# ESP32-S31 register map
Vendor: ESPRESSIF SYSTEMS (SHANGHAI) CO., LTD.; Series: ESP32 S-Series; File version: 1
CPU: RV32IMAFC r0p0, little endian, no MPU, FPU, 0 interrupt priority bits
Address unit: 32 bits
Registers are 32-bit, read-write, reset 0x0 unless marked. A register's access mark holds for its fields unless they carry their own. Offsets are from the block's base; [hi:lo] are bit positions; {n}, {i} and the like mark numbered series; 'fields as' and 'values as' point back to an identical list.

## HP_SYS_CLKRST — HP_SYS_CLKRST Peripheral
Base 0x20587000
0x00 SOC_CLK_SEL — need_des
  [1:0] REG_SOC_CLK_SEL — Configures to select the clock source of HP_ROOT_CLK.\\ 0 (default): XTAL_CLK\\ 1: PLL_F300M_CLK\\ 2: RC_FAST_CLK\\
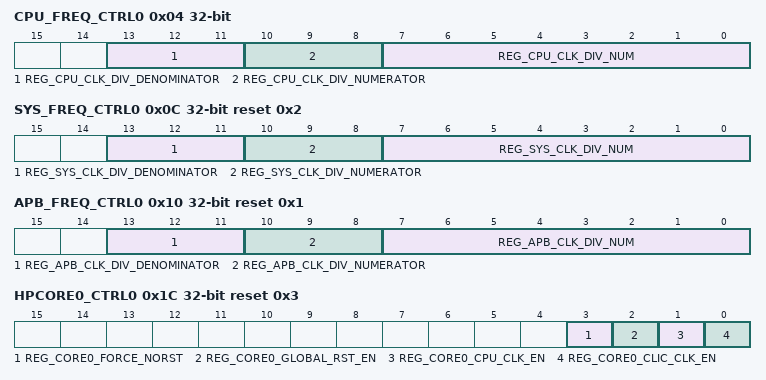
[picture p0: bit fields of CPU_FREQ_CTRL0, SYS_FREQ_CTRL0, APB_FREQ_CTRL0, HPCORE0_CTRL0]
0x04 CPU_FREQ_CTRL0 — need_des
  [13:11] REG_CPU_CLK_DIV_DENOMINATOR — need_des
  [10:8] REG_CPU_CLK_DIV_NUMERATOR — need_des
  [7:0] REG_CPU_CLK_DIV_NUM — need_des
0x08 MEM_FREQ_CTRL0 reset 0x1 — need_des
  [0] REG_MEM_CLK_DIV_NUM
0x0C SYS_FREQ_CTRL0 reset 0x2 — need_des
  [13:11] REG_SYS_CLK_DIV_DENOMINATOR — need_des
  [10:8] REG_SYS_CLK_DIV_NUMERATOR — need_des
  [7:0] REG_SYS_CLK_DIV_NUM — need_des
0x10 APB_FREQ_CTRL0 reset 0x1 — need_des
  [13:11] REG_APB_CLK_DIV_DENOMINATOR — need_des
  [10:8] REG_APB_CLK_DIV_NUMERATOR — need_des
  [7:0] REG_APB_CLK_DIV_NUM — need_des
0x14 ROOT_CLK_CTRL0 — need_des
  [0] REG_SOC_CLK_UPDATE
0x18 CPU_WFI_DELAY_CTRL0 — need_des
  [3:0] REG_CPUICM_DELAY_NUM
0x1C HPCORE0_CTRL0 reset 0x3 — need_des
  [3] REG_CORE0_FORCE_NORST — need_des
  [2] REG_CORE0_GLOBAL_RST_EN — need_des
  [1] REG_CORE0_CPU_CLK_EN — need_des
  [0] REG_CORE0_CLIC_CLK_EN — need_des
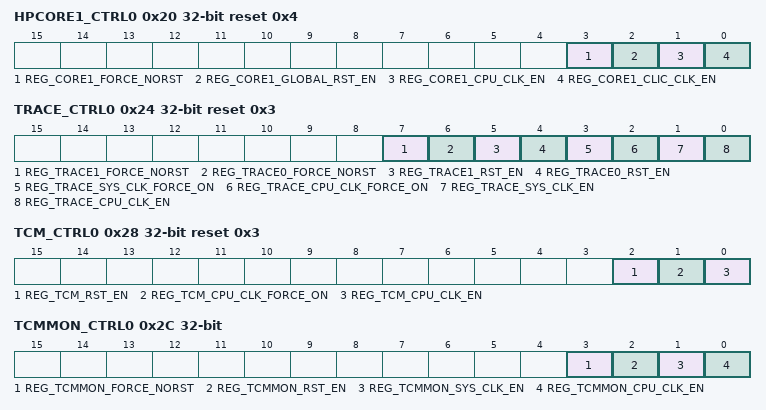
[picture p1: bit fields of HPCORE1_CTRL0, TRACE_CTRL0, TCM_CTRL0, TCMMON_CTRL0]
0x20 HPCORE1_CTRL0 reset 0x4 — need_des
  [3] REG_CORE1_FORCE_NORST — need_des
  [2] REG_CORE1_GLOBAL_RST_EN — need_des
  [1] REG_CORE1_CPU_CLK_EN — need_des
  [0] REG_CORE1_CLIC_CLK_EN — need_des
0x24 TRACE_CTRL0 reset 0x3 — need_des
  [7] REG_TRACE1_FORCE_NORST — need_des
  [6] REG_TRACE0_FORCE_NORST — need_des
  [5] REG_TRACE1_RST_EN — need_des
  [4] REG_TRACE0_RST_EN — need_des
  [3] REG_TRACE_SYS_CLK_FORCE_ON — need_des
  [2] REG_TRACE_CPU_CLK_FORCE_ON — need_des
  [1] REG_TRACE_SYS_CLK_EN — need_des
  [0] REG_TRACE_CPU_CLK_EN — need_des
0x28 TCM_CTRL0 reset 0x3 — need_des
  [2] REG_TCM_RST_EN — need_des
  [1] REG_TCM_CPU_CLK_FORCE_ON — need_des
  [0] REG_TCM_CPU_CLK_EN — need_des
0x2C TCMMON_CTRL0 — need_des
  [3] REG_TCMMON_FORCE_NORST — need_des
  [2] REG_TCMMON_RST_EN — need_des
  [1] REG_TCMMON_SYS_CLK_EN — need_des
  [0] REG_TCMMON_CPU_CLK_EN — need_des
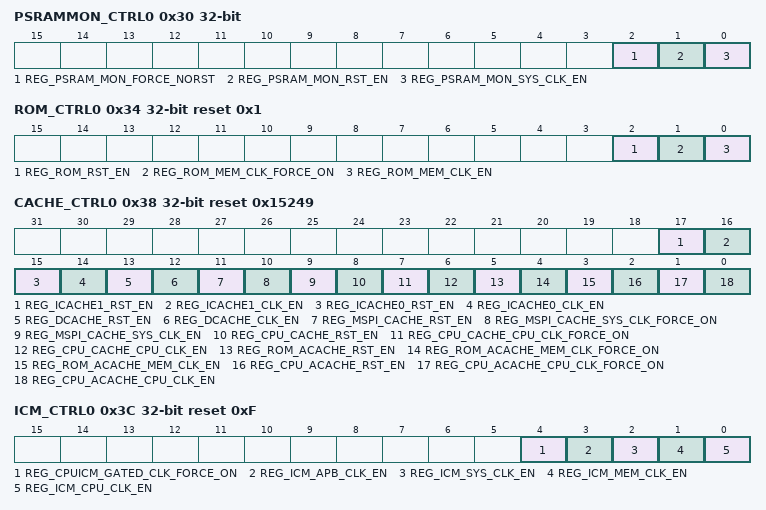
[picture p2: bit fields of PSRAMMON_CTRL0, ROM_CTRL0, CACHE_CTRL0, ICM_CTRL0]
0x30 PSRAMMON_CTRL0 — need_des
  [2] REG_PSRAM_MON_FORCE_NORST — need_des
  [1] REG_PSRAM_MON_RST_EN — need_des
  [0] REG_PSRAM_MON_SYS_CLK_EN — need_des
0x34 ROM_CTRL0 reset 0x1 — need_des
  [2] REG_ROM_RST_EN — need_des
  [1] REG_ROM_MEM_CLK_FORCE_ON — need_des
  [0] REG_ROM_MEM_CLK_EN — need_des
0x38 CACHE_CTRL0 reset 0x15249 — need_des
  [17] REG_ICACHE1_RST_EN — need_des
  [16] REG_ICACHE1_CLK_EN — need_des
  [15] REG_ICACHE0_RST_EN — need_des
  [14] REG_ICACHE0_CLK_EN — need_des
  [13] REG_DCACHE_RST_EN — need_des
  [12] REG_DCACHE_CLK_EN — need_des
  [11] REG_MSPI_CACHE_RST_EN — need_des
  [10] REG_MSPI_CACHE_SYS_CLK_FORCE_ON — need_des
  [9] REG_MSPI_CACHE_SYS_CLK_EN — need_des
  [8] REG_CPU_CACHE_RST_EN — need_des
  [7] REG_CPU_CACHE_CPU_CLK_FORCE_ON — need_des
  [6] REG_CPU_CACHE_CPU_CLK_EN — need_des
  [5] REG_ROM_ACACHE_RST_EN — need_des
  [4] REG_ROM_ACACHE_MEM_CLK_FORCE_ON — need_des
  [3] REG_ROM_ACACHE_MEM_CLK_EN — need_des
  [2] REG_CPU_ACACHE_RST_EN — need_des
  [1] REG_CPU_ACACHE_CPU_CLK_FORCE_ON — need_des
  [0] REG_CPU_ACACHE_CPU_CLK_EN — need_des
0x3C ICM_CTRL0 reset 0xF — need_des
  [4] REG_CPUICM_GATED_CLK_FORCE_ON — need_des
  [3] REG_ICM_APB_CLK_EN — need_des
  [2] REG_ICM_SYS_CLK_EN — need_des
  [1] REG_ICM_MEM_CLK_EN — need_des
  [0] REG_ICM_CPU_CLK_EN — need_des
0x40 MODEM_CTRL0 reset 0x1 — need_des
  [0] REG_MODEM_CLK_EN
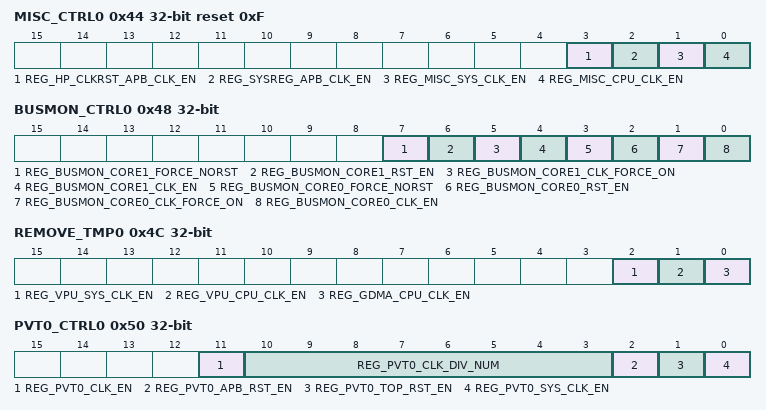
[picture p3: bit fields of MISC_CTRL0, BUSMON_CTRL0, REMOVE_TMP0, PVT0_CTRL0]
0x44 MISC_CTRL0 reset 0xF — need_des
  [3] REG_HP_CLKRST_APB_CLK_EN — need_des
  [2] REG_SYSREG_APB_CLK_EN — need_des
  [1] REG_MISC_SYS_CLK_EN — need_des
  [0] REG_MISC_CPU_CLK_EN — need_des
0x48 BUSMON_CTRL0 — need_des
  [7] REG_BUSMON_CORE1_FORCE_NORST — need_des
  [6] REG_BUSMON_CORE1_RST_EN — need_des
  [5] REG_BUSMON_CORE1_CLK_FORCE_ON — need_des
  [4] REG_BUSMON_CORE1_CLK_EN — need_des
  [3] REG_BUSMON_CORE0_FORCE_NORST — need_des
  [2] REG_BUSMON_CORE0_RST_EN — need_des
  [1] REG_BUSMON_CORE0_CLK_FORCE_ON — need_des
  [0] REG_BUSMON_CORE0_CLK_EN — need_des
0x4C REMOVE_TMP0 — need_des
  [2] REG_VPU_SYS_CLK_EN — need_des
  [1] REG_VPU_CPU_CLK_EN — need_des
  [0] REG_GDMA_CPU_CLK_EN — need_des
0x50 PVT0_CTRL0 — need_des
  [11] REG_PVT0_CLK_EN — need_des
  [10:3] REG_PVT0_CLK_DIV_NUM — need_des
  [2] REG_PVT0_APB_RST_EN — need_des
  [1] REG_PVT0_TOP_RST_EN — need_des
  [0] REG_PVT0_SYS_CLK_EN — need_des
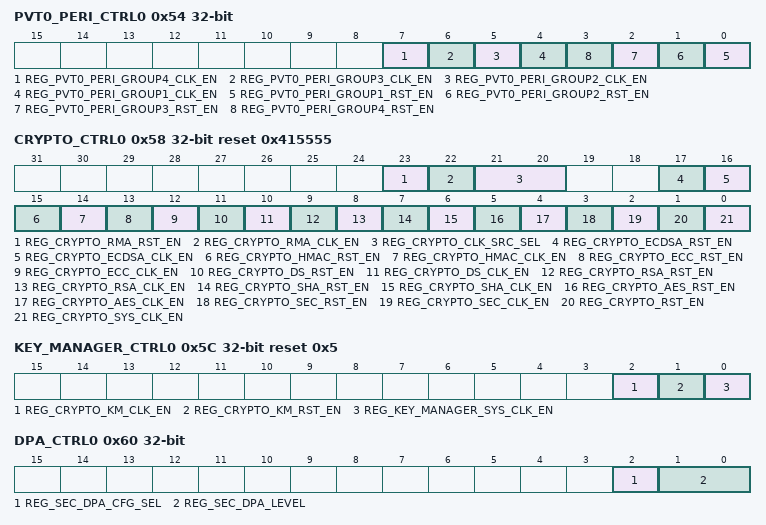
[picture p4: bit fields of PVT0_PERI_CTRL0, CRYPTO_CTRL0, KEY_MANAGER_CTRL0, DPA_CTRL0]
0x54 PVT0_PERI_CTRL0 — need_des
  [7] REG_PVT0_PERI_GROUP4_CLK_EN — modem power domian pvt clk en
  [6] REG_PVT0_PERI_GROUP3_CLK_EN — modem power domian pvt clk en
  [5] REG_PVT0_PERI_GROUP2_CLK_EN — TOP power domian pvt clk en
  [4] REG_PVT0_PERI_GROUP1_CLK_EN — TOP power domian pvt clk en
  [n-1] REG_PVT0_PERI_GROUP{n}_RST_EN (n=1..4) — need_des
0x58 CRYPTO_CTRL0 reset 0x415555 — need_des
  [23] REG_CRYPTO_RMA_RST_EN — need_des
  [22] REG_CRYPTO_RMA_CLK_EN — need_des
  [21:20] REG_CRYPTO_CLK_SRC_SEL — need_des
  [17] REG_CRYPTO_ECDSA_RST_EN — need_des
  [16] REG_CRYPTO_ECDSA_CLK_EN — need_des
  [15] REG_CRYPTO_HMAC_RST_EN — need_des
  [14] REG_CRYPTO_HMAC_CLK_EN — need_des
  [13] REG_CRYPTO_ECC_RST_EN — need_des
  [12] REG_CRYPTO_ECC_CLK_EN — need_des
  [11] REG_CRYPTO_DS_RST_EN — need_des
  [10] REG_CRYPTO_DS_CLK_EN — need_des
  [9] REG_CRYPTO_RSA_RST_EN — need_des
  [8] REG_CRYPTO_RSA_CLK_EN — need_des
  [7] REG_CRYPTO_SHA_RST_EN — need_des
  [6] REG_CRYPTO_SHA_CLK_EN — need_des
  [5] REG_CRYPTO_AES_RST_EN — need_des
  [4] REG_CRYPTO_AES_CLK_EN — need_des
  [3] REG_CRYPTO_SEC_RST_EN — need_des
  [2] REG_CRYPTO_SEC_CLK_EN — need_des
  [1] REG_CRYPTO_RST_EN — need_des
  [0] REG_CRYPTO_SYS_CLK_EN — need_des
0x5C KEY_MANAGER_CTRL0 reset 0x5 — need_des
  [2] REG_CRYPTO_KM_CLK_EN — need_des
  [1] REG_CRYPTO_KM_RST_EN — need_des
  [0] REG_KEY_MANAGER_SYS_CLK_EN — need_des
0x60 DPA_CTRL0 — need_des
  [2] REG_SEC_DPA_CFG_SEL — need_des
  [1:0] REG_SEC_DPA_LEVEL — need_des
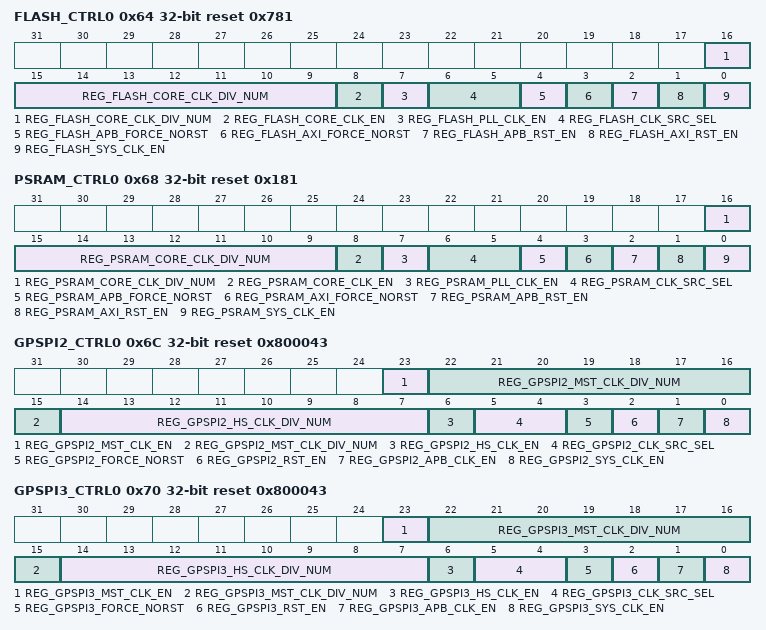
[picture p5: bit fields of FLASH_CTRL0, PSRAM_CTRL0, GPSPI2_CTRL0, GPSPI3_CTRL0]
0x64 FLASH_CTRL0 reset 0x781 — need_des
  [16:9] REG_FLASH_CORE_CLK_DIV_NUM — need_des
  [8] REG_FLASH_CORE_CLK_EN — need_des
  [7] REG_FLASH_PLL_CLK_EN — need_des
  [6:5] REG_FLASH_CLK_SRC_SEL — need_des
  [4] REG_FLASH_APB_FORCE_NORST — need_des
  [3] REG_FLASH_AXI_FORCE_NORST — need_des
  [2] REG_FLASH_APB_RST_EN — need_des
  [1] REG_FLASH_AXI_RST_EN — need_des
  [0] REG_FLASH_SYS_CLK_EN — need_des
0x68 PSRAM_CTRL0 reset 0x181 — need_des
  [16:9] REG_PSRAM_CORE_CLK_DIV_NUM — need_des
  [8] REG_PSRAM_CORE_CLK_EN — need_des
  [7] REG_PSRAM_PLL_CLK_EN — need_des
  [6:5] REG_PSRAM_CLK_SRC_SEL — need_des
  [4] REG_PSRAM_APB_FORCE_NORST — need_des
  [3] REG_PSRAM_AXI_FORCE_NORST — need_des
  [2] REG_PSRAM_APB_RST_EN — need_des
  [1] REG_PSRAM_AXI_RST_EN — need_des
  [0] REG_PSRAM_SYS_CLK_EN — need_des
0x6C GPSPI2_CTRL0 reset 0x800043 — need_des
  [23] REG_GPSPI2_MST_CLK_EN — need_des
  [22:15] REG_GPSPI2_MST_CLK_DIV_NUM — need_des
  [14:7] REG_GPSPI2_HS_CLK_DIV_NUM — need_des
  [6] REG_GPSPI2_HS_CLK_EN — need_des
  [5:4] REG_GPSPI2_CLK_SRC_SEL — need_des
  [3] REG_GPSPI2_FORCE_NORST — need_des
  [2] REG_GPSPI2_RST_EN — need_des
  [1] REG_GPSPI2_APB_CLK_EN — need_des
  [0] REG_GPSPI2_SYS_CLK_EN — need_des
0x70 GPSPI3_CTRL0 reset 0x800043 — need_des
  [23] REG_GPSPI3_MST_CLK_EN — need_des
  [22:15] REG_GPSPI3_MST_CLK_DIV_NUM — need_des
  [14:7] REG_GPSPI3_HS_CLK_DIV_NUM — need_des
  [6] REG_GPSPI3_HS_CLK_EN — need_des
  [5:4] REG_GPSPI3_CLK_SRC_SEL — need_des
  [3] REG_GPSPI3_FORCE_NORST — need_des
  [2] REG_GPSPI3_RST_EN — need_des
  [1] REG_GPSPI3_APB_CLK_EN — need_des
  [0] REG_GPSPI3_SYS_CLK_EN — need_des
0x74 GDMA_CTRL0 — need_des
  [0] REG_GDMA_SYS_CLK_EN
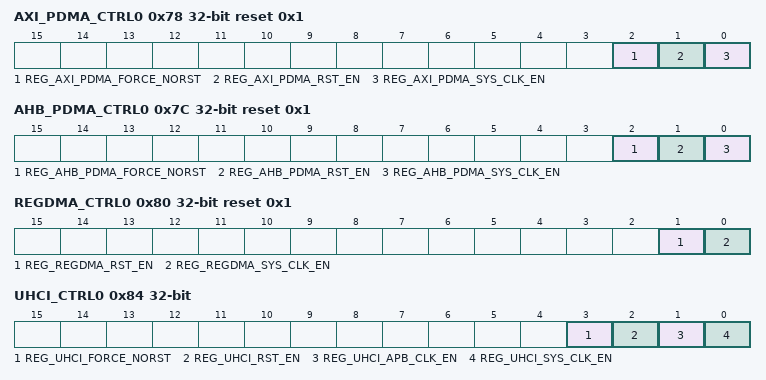
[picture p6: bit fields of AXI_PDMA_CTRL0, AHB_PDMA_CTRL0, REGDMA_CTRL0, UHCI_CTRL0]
0x78 AXI_PDMA_CTRL0 reset 0x1 — need_des
  [2] REG_AXI_PDMA_FORCE_NORST — need_des
  [1] REG_AXI_PDMA_RST_EN — need_des
  [0] REG_AXI_PDMA_SYS_CLK_EN — need_des
0x7C AHB_PDMA_CTRL0 reset 0x1 — need_des
  [2] REG_AHB_PDMA_FORCE_NORST — need_des
  [1] REG_AHB_PDMA_RST_EN — need_des
  [0] REG_AHB_PDMA_SYS_CLK_EN — need_des
0x80 REGDMA_CTRL0 reset 0x1 — need_des
  [1] REG_REGDMA_RST_EN — need_des
  [0] REG_REGDMA_SYS_CLK_EN — need_des
0x84 UHCI_CTRL0 — need_des
  [3] REG_UHCI_FORCE_NORST — need_des
  [2] REG_UHCI_RST_EN — need_des
  [1] REG_UHCI_APB_CLK_EN — need_des
  [0] REG_UHCI_SYS_CLK_EN — need_des
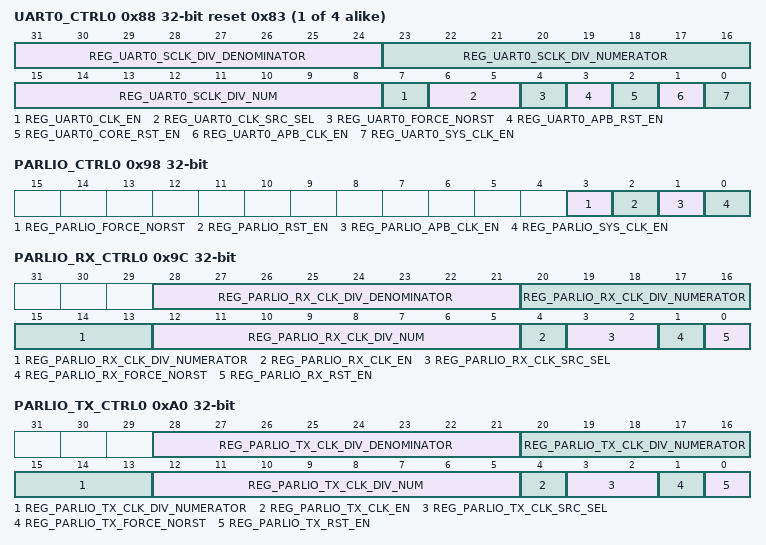
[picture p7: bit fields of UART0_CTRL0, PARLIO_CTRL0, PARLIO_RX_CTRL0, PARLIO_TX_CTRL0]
{0x88+4i} UART{i}_CTRL0 reset 0x83 (i=0..3) — need_des
  [31:24] REG_UART{i}_SCLK_DIV_DENOMINATOR — need_des
  [23:16] REG_UART{i}_SCLK_DIV_NUMERATOR — need_des
  [15:8] REG_UART{i}_SCLK_DIV_NUM — need_des
  [7] REG_UART{i}_CLK_EN — need_des
  [6:5] REG_UART{i}_CLK_SRC_SEL — need_des
  [4] REG_UART{i}_FORCE_NORST — need_des
  [3] REG_UART{i}_APB_RST_EN — need_des
  [2] REG_UART{i}_CORE_RST_EN — need_des
  [1] REG_UART{i}_APB_CLK_EN — need_des
  [0] REG_UART{i}_SYS_CLK_EN — need_des
0x98 PARLIO_CTRL0 — need_des
  [3] REG_PARLIO_FORCE_NORST — need_des
  [2] REG_PARLIO_RST_EN — need_des
  [1] REG_PARLIO_APB_CLK_EN — need_des
  [0] REG_PARLIO_SYS_CLK_EN — need_des
0x9C PARLIO_RX_CTRL0 — need_des
  [28:21] REG_PARLIO_RX_CLK_DIV_DENOMINATOR — need_des
  [20:13] REG_PARLIO_RX_CLK_DIV_NUMERATOR — need_des
  [12:5] REG_PARLIO_RX_CLK_DIV_NUM — need_des
  [4] REG_PARLIO_RX_CLK_EN — need_des
  [3:2] REG_PARLIO_RX_CLK_SRC_SEL — need_des
  [1] REG_PARLIO_RX_FORCE_NORST — need_des
  [0] REG_PARLIO_RX_RST_EN — need_des
0xA0 PARLIO_TX_CTRL0 — need_des
  [28:21] REG_PARLIO_TX_CLK_DIV_DENOMINATOR — need_des
  [20:13] REG_PARLIO_TX_CLK_DIV_NUMERATOR — need_des
  [12:5] REG_PARLIO_TX_CLK_DIV_NUM — need_des
  [4] REG_PARLIO_TX_CLK_EN — need_des
  [3:2] REG_PARLIO_TX_CLK_SRC_SEL — need_des
  [1] REG_PARLIO_TX_FORCE_NORST — need_des
  [0] REG_PARLIO_TX_RST_EN — need_des
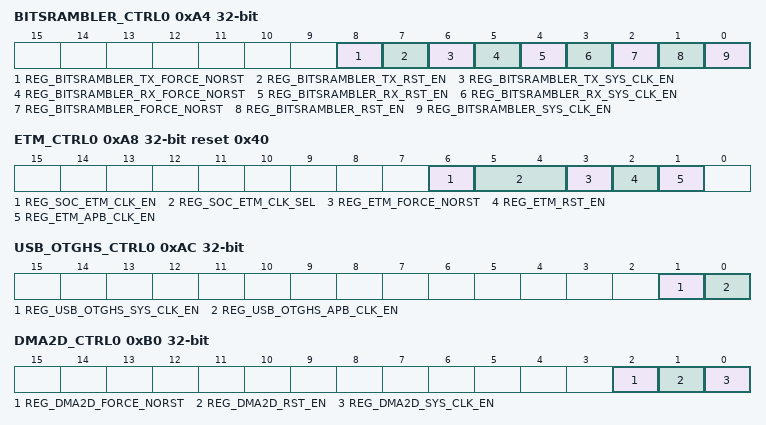
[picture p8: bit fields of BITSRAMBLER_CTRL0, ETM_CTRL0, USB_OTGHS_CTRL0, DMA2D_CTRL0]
0xA4 BITSRAMBLER_CTRL0 — need_des
  [8] REG_BITSRAMBLER_TX_FORCE_NORST — need_des
  [7] REG_BITSRAMBLER_TX_RST_EN — need_des
  [6] REG_BITSRAMBLER_TX_SYS_CLK_EN — need_des
  [5] REG_BITSRAMBLER_RX_FORCE_NORST — need_des
  [4] REG_BITSRAMBLER_RX_RST_EN — need_des
  [3] REG_BITSRAMBLER_RX_SYS_CLK_EN — need_des
  [2] REG_BITSRAMBLER_FORCE_NORST — need_des
  [1] REG_BITSRAMBLER_RST_EN — need_des
  [0] REG_BITSRAMBLER_SYS_CLK_EN — need_des
0xA8 ETM_CTRL0 reset 0x40 — need_des
  [6] REG_SOC_ETM_CLK_EN — need_des
  [5:4] REG_SOC_ETM_CLK_SEL — need_des
  [3] REG_ETM_FORCE_NORST — need_des
  [2] REG_ETM_RST_EN — need_des
  [1] REG_ETM_APB_CLK_EN — need_des
0xAC USB_OTGHS_CTRL0 — need_des
  [1] REG_USB_OTGHS_SYS_CLK_EN — need_des
  [0] REG_USB_OTGHS_APB_CLK_EN — need_des
0xB0 DMA2D_CTRL0 — need_des
  [2] REG_DMA2D_FORCE_NORST — need_des
  [1] REG_DMA2D_RST_EN — need_des
  [0] REG_DMA2D_SYS_CLK_EN — need_des
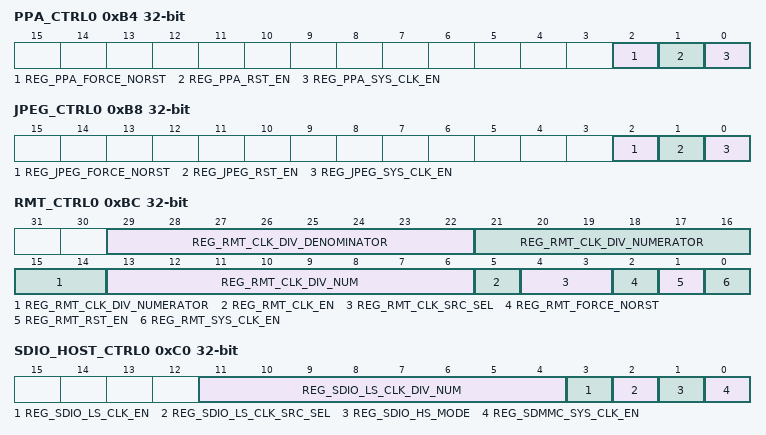
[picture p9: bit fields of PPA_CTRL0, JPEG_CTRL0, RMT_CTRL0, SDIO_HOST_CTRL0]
0xB4 PPA_CTRL0 — need_des
  [2] REG_PPA_FORCE_NORST — need_des
  [1] REG_PPA_RST_EN — need_des
  [0] REG_PPA_SYS_CLK_EN — need_des
0xB8 JPEG_CTRL0 — need_des
  [2] REG_JPEG_FORCE_NORST — need_des
  [1] REG_JPEG_RST_EN — need_des
  [0] REG_JPEG_SYS_CLK_EN — need_des
0xBC RMT_CTRL0 — need_des
  [29:22] REG_RMT_CLK_DIV_DENOMINATOR — need_des
  [21:14] REG_RMT_CLK_DIV_NUMERATOR — need_des
  [13:6] REG_RMT_CLK_DIV_NUM — need_des
  [5] REG_RMT_CLK_EN — need_des
  [4:3] REG_RMT_CLK_SRC_SEL — need_des
  [2] REG_RMT_FORCE_NORST — need_des
  [1] REG_RMT_RST_EN — need_des
  [0] REG_RMT_SYS_CLK_EN — need_des
0xC0 SDIO_HOST_CTRL0 — need_des
  [11:4] REG_SDIO_LS_CLK_DIV_NUM — need_des
  [3] REG_SDIO_LS_CLK_EN — need_des
  [2] REG_SDIO_LS_CLK_SRC_SEL — reserved
  [1] REG_SDIO_HS_MODE — reserved
  [0] REG_SDMMC_SYS_CLK_EN — need_des
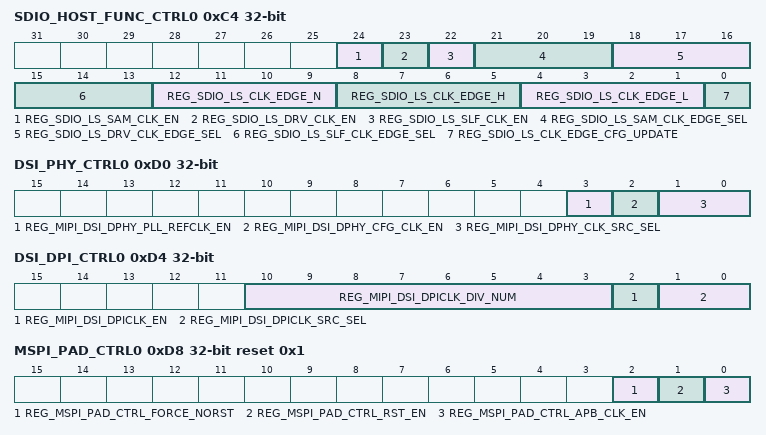
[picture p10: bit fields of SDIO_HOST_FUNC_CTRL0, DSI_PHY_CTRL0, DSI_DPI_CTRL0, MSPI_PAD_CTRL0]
0xC4 SDIO_HOST_FUNC_CTRL0 access per field — need_des
  [24] REG_SDIO_LS_SAM_CLK_EN rw — need_des
  [23] REG_SDIO_LS_DRV_CLK_EN rw — need_des
  [22] REG_SDIO_LS_SLF_CLK_EN rw — need_des
  [21:19] REG_SDIO_LS_SAM_CLK_EDGE_SEL rw — need_des
  [18:16] REG_SDIO_LS_DRV_CLK_EDGE_SEL rw — need_des
  [15:13] REG_SDIO_LS_SLF_CLK_EDGE_SEL rw — need_des
  [12:9] REG_SDIO_LS_CLK_EDGE_N rw — need_des
  [8:5] REG_SDIO_LS_CLK_EDGE_H rw — need_des
  [4:1] REG_SDIO_LS_CLK_EDGE_L rw — need_des
  [0] REG_SDIO_LS_CLK_EDGE_CFG_UPDATE wo — need_des
0xC8 EMAC_CTRL0 — need_des
  [0] REG_EMAC_SYS_CLK_EN
0xCC DSI_CTRL0 — need_des
  [0] REG_DSI_SYS_CLK_EN
0xD0 DSI_PHY_CTRL0 — need_des
  [3] REG_MIPI_DSI_DPHY_PLL_REFCLK_EN — need_des
  [2] REG_MIPI_DSI_DPHY_CFG_CLK_EN — need_des
  [1:0] REG_MIPI_DSI_DPHY_CLK_SRC_SEL — need_des
0xD4 DSI_DPI_CTRL0 — need_des
  [10:3] REG_MIPI_DSI_DPICLK_DIV_NUM — need_des
  [2] REG_MIPI_DSI_DPICLK_EN — need_des
  [1:0] REG_MIPI_DSI_DPICLK_SRC_SEL — need_des
0xD8 MSPI_PAD_CTRL0 reset 0x1 — need_des
  [2] REG_MSPI_PAD_CTRL_FORCE_NORST — need_des
  [1] REG_MSPI_PAD_CTRL_RST_EN — need_des
  [0] REG_MSPI_PAD_CTRL_APB_CLK_EN — need_des
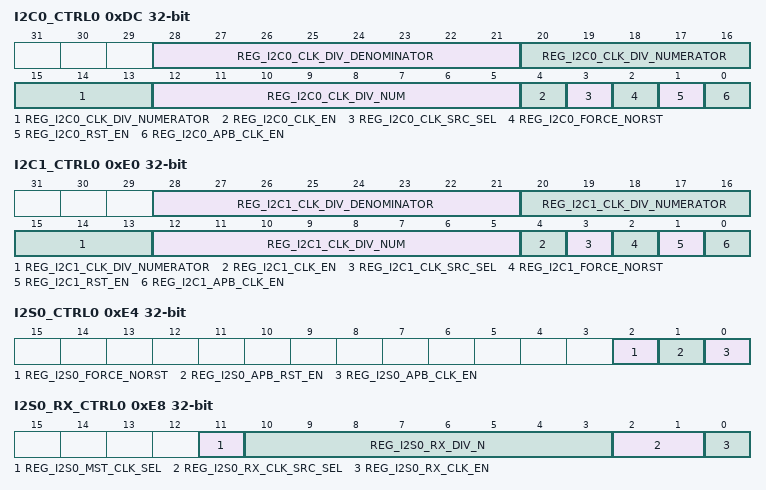
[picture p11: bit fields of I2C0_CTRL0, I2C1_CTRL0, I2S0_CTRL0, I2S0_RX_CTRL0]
0xDC I2C0_CTRL0 — need_des
  [28:21] REG_I2C0_CLK_DIV_DENOMINATOR — need_des
  [20:13] REG_I2C0_CLK_DIV_NUMERATOR — need_des
  [12:5] REG_I2C0_CLK_DIV_NUM — need_des
  [4] REG_I2C0_CLK_EN — need_des
  [3] REG_I2C0_CLK_SRC_SEL — need_des
  [2] REG_I2C0_FORCE_NORST — need_des
  [1] REG_I2C0_RST_EN — need_des
  [0] REG_I2C0_APB_CLK_EN — need_des
0xE0 I2C1_CTRL0 — need_des
  [28:21] REG_I2C1_CLK_DIV_DENOMINATOR — need_des
  [20:13] REG_I2C1_CLK_DIV_NUMERATOR — need_des
  [12:5] REG_I2C1_CLK_DIV_NUM — need_des
  [4] REG_I2C1_CLK_EN — need_des
  [3] REG_I2C1_CLK_SRC_SEL — need_des
  [2] REG_I2C1_FORCE_NORST — need_des
  [1] REG_I2C1_RST_EN — need_des
  [0] REG_I2C1_APB_CLK_EN — need_des
0xE4 I2S0_CTRL0 — need_des
  [2] REG_I2S0_FORCE_NORST — need_des
  [1] REG_I2S0_APB_RST_EN — need_des
  [0] REG_I2S0_APB_CLK_EN — need_des
0xE8 I2S0_RX_CTRL0 — need_des
  [11] REG_I2S0_MST_CLK_SEL — need_des
  [10:3] REG_I2S0_RX_DIV_N — need_des
  [2:1] REG_I2S0_RX_CLK_SRC_SEL — need_des
  [0] REG_I2S0_RX_CLK_EN — need_des
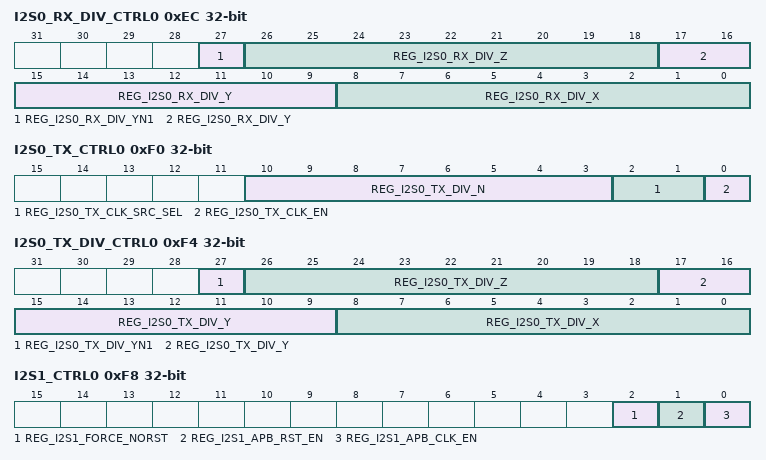
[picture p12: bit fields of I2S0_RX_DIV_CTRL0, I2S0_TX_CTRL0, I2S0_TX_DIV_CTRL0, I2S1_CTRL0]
0xEC I2S0_RX_DIV_CTRL0 — need_des
  [27] REG_I2S0_RX_DIV_YN1 — need_des
  [26:18] REG_I2S0_RX_DIV_Z — need_des
  [17:9] REG_I2S0_RX_DIV_Y — need_des
  [8:0] REG_I2S0_RX_DIV_X — need_des
0xF0 I2S0_TX_CTRL0 — need_des
  [10:3] REG_I2S0_TX_DIV_N — need_des
  [2:1] REG_I2S0_TX_CLK_SRC_SEL — need_des
  [0] REG_I2S0_TX_CLK_EN — need_des
0xF4 I2S0_TX_DIV_CTRL0 — need_des
  [27] REG_I2S0_TX_DIV_YN1 — need_des
  [26:18] REG_I2S0_TX_DIV_Z — need_des
  [17:9] REG_I2S0_TX_DIV_Y — need_des
  [8:0] REG_I2S0_TX_DIV_X — need_des
0xF8 I2S1_CTRL0 — need_des
  [2] REG_I2S1_FORCE_NORST — need_des
  [1] REG_I2S1_APB_RST_EN — need_des
  [0] REG_I2S1_APB_CLK_EN — need_des
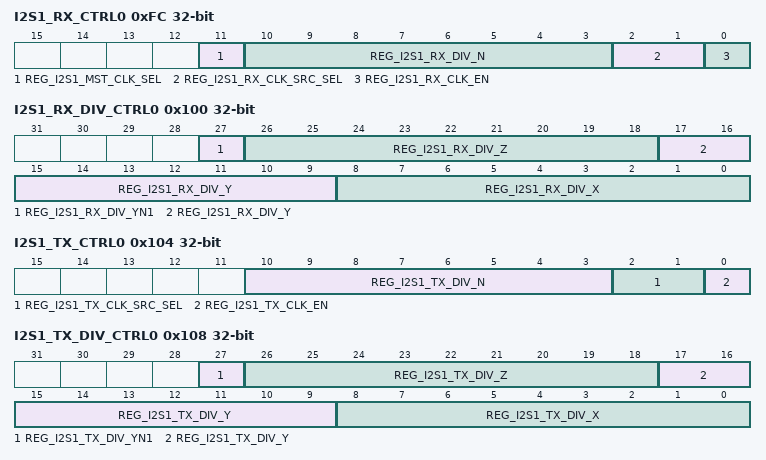
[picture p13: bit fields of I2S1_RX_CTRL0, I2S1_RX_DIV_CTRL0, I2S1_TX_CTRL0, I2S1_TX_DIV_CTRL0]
0xFC I2S1_RX_CTRL0 — need_des
  [11] REG_I2S1_MST_CLK_SEL — need_des
  [10:3] REG_I2S1_RX_DIV_N — need_des
  [2:1] REG_I2S1_RX_CLK_SRC_SEL — need_des
  [0] REG_I2S1_RX_CLK_EN — need_des
0x100 I2S1_RX_DIV_CTRL0 — need_des
  [27] REG_I2S1_RX_DIV_YN1 — need_des
  [26:18] REG_I2S1_RX_DIV_Z — need_des
  [17:9] REG_I2S1_RX_DIV_Y — need_des
  [8:0] REG_I2S1_RX_DIV_X — need_des
0x104 I2S1_TX_CTRL0 — need_des
  [10:3] REG_I2S1_TX_DIV_N — need_des
  [2:1] REG_I2S1_TX_CLK_SRC_SEL — need_des
  [0] REG_I2S1_TX_CLK_EN — need_des
0x108 I2S1_TX_DIV_CTRL0 — need_des
  [27] REG_I2S1_TX_DIV_YN1 — need_des
  [26:18] REG_I2S1_TX_DIV_Z — need_des
  [17:9] REG_I2S1_TX_DIV_Y — need_des
  [8:0] REG_I2S1_TX_DIV_X — need_des
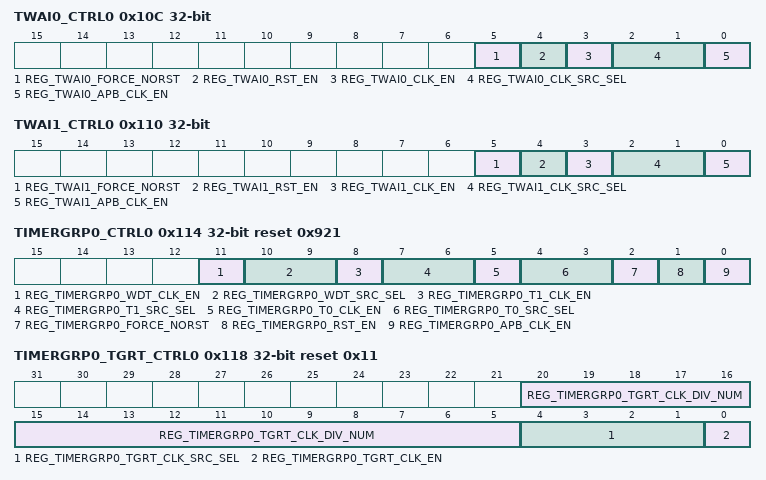
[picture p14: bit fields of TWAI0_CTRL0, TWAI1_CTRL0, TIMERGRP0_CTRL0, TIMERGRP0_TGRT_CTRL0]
0x10C TWAI0_CTRL0 — need_des
  [5] REG_TWAI0_FORCE_NORST — need_des
  [4] REG_TWAI0_RST_EN — need_des
  [3] REG_TWAI0_CLK_EN — need_des
  [2:1] REG_TWAI0_CLK_SRC_SEL — need_des
  [0] REG_TWAI0_APB_CLK_EN — need_des
0x110 TWAI1_CTRL0 — need_des
  [5] REG_TWAI1_FORCE_NORST — need_des
  [4] REG_TWAI1_RST_EN — need_des
  [3] REG_TWAI1_CLK_EN — need_des
  [2:1] REG_TWAI1_CLK_SRC_SEL — need_des
  [0] REG_TWAI1_APB_CLK_EN — need_des
0x114 TIMERGRP0_CTRL0 reset 0x921 — need_des
  [11] REG_TIMERGRP0_WDT_CLK_EN — need_des
  [10:9] REG_TIMERGRP0_WDT_SRC_SEL — need_des
  [8] REG_TIMERGRP0_T1_CLK_EN — need_des
  [7:6] REG_TIMERGRP0_T1_SRC_SEL — need_des
  [5] REG_TIMERGRP0_T0_CLK_EN — need_des
  [4:3] REG_TIMERGRP0_T0_SRC_SEL — need_des
  [2] REG_TIMERGRP0_FORCE_NORST — need_des
  [1] REG_TIMERGRP0_RST_EN — need_des
  [0] REG_TIMERGRP0_APB_CLK_EN — need_des
0x118 TIMERGRP0_TGRT_CTRL0 reset 0x11 — need_des
  [20:5] REG_TIMERGRP0_TGRT_CLK_DIV_NUM — need_des
  [4:1] REG_TIMERGRP0_TGRT_CLK_SRC_SEL — need_des
  [0] REG_TIMERGRP0_TGRT_CLK_EN — need_des
0x11C TIMERGRP1_CTRL0 reset 0x921 — need_des
  [11] REG_TIMERGRP1_WDT_CLK_EN — need_des
  [10:9] REG_TIMERGRP1_WDT_SRC_SEL — need_des
  [8] REG_TIMERGRP1_T1_CLK_EN — need_des
  [7:6] REG_TIMERGRP1_T1_SRC_SEL — need_des
  [5] REG_TIMERGRP1_T0_CLK_EN — need_des
  [4:3] REG_TIMERGRP1_T0_SRC_SEL — need_des
  [2] REG_TIMERGRP1_FORCE_NORST — need_des
  [1] REG_TIMERGRP1_RST_EN — need_des
  [0] REG_TIMERGRP1_APB_CLK_EN — need_des
0x120 SYSTIMER_CTRL0 — need_des
  [4] REG_SYSTIMER_CLK_EN — need_des
  [3] REG_SYSTIMER_CLK_SRC_SEL — need_des
  [2] REG_SYSTIMER_FORCE_NORST — need_des
  [1] REG_SYSTIMER_RST_EN — need_des
  [0] REG_SYSTIMER_APB_CLK_EN — need_des
{0x124+4i} MCPWM{i}_CTRL0 (i=0..3) — need_des
  [13:6] REG_MCPWM{i}_CLK_DIV_NUM — need_des
  [5] REG_MCPWM{i}_CLK_EN — need_des
  [4:3] REG_MCPWM{i}_CLK_SRC_SEL — need_des
  [2] REG_MCPWM{i}_FORCE_NORST — need_des
  [1] REG_MCPWM{i}_RST_EN — need_des
  [0] REG_MCPWM{i}_APB_CLK_EN — need_des
0x134 INTRMTX_CTRL0 reset 0x1 — need_des
  [2] REG_INTRMTX_FORCE_NORST — need_des
  [1] REG_INTRMTX_RST_EN — need_des
  [0] REG_INTRMTX_APB_CLK_EN — need_des
0x138 PCNT_CTRL0 — need_des
  [5] REG_PCNT1_FORCE_NORST — need_des
  [4] REG_PCNT1_RST_EN — need_des
  [3] REG_PCNT1_APB_CLK_EN — need_des
  [2] REG_PCNT0_FORCE_NORST — need_des
  [1] REG_PCNT0_RST_EN — need_des
  [0] REG_PCNT0_APB_CLK_EN — need_des
0x144 USB_DEVICE_CTRL0 reset 0x1 — need_des
  [0] REG_USB_DEVICE_APB_CLK_EN
0x148 LEDC_CTRL0 — need_des
  [11] REG_LEDC1_CLK_EN — need_des
  [10:9] REG_LEDC1_CLK_SRC_SEL — need_des
  [8] REG_LEDC1_FORCE_NORST — need_des
  [7] REG_LEDC1_RST_EN — need_des
  [6] REG_LEDC1_APB_CLK_EN — need_des
  [5] REG_LEDC0_CLK_EN — need_des
  [4:3] REG_LEDC0_CLK_SRC_SEL — need_des
  [2] REG_LEDC0_FORCE_NORST — need_des
  [1] REG_LEDC0_RST_EN — need_des
  [0] REG_LEDC0_APB_CLK_EN — need_des
0x14C LCDCAM_CTRL0 — need_des
  [4] REG_LCDCAM_FORCE_NORST — need_des
  [3] REG_LCDCAM_RST_EN — need_des
  [2] REG_LCDCAM_SYS_CLK_EN — need_des
  [1] REG_LCDCAM_APB_RST_EN — need_des
  [0] REG_LCDCAM_APB_CLK_EN — need_des
0x150 LCDCAM_LCD_CTRL0 — need_des
  [26:19] REG_LCD_CLK_DIV_DENOMINATOR — need_des
  [18:11] REG_LCD_CLK_DIV_NUMERATOR — need_des
  [10:3] REG_LCD_CLK_DIV_NUM — need_des
  [2] REG_LCD_CLK_EN — need_des
  [1:0] REG_LCD_CLK_SRC_SEL — need_des
0x154 LCDCAM_LCDCAM_CTRL0 — need_des
  [26:19] REG_LCDCAM_CLK_DIV_DENOMINATOR — need_des
  [18:11] REG_LCDCAM_CLK_DIV_NUMERATOR — need_des
  [10:3] REG_LCDCAM_CLK_DIV_NUM — need_des
  [2] REG_LCDCAM_CLK_EN — need_des
  [1:0] REG_LCDCAM_CLK_SRC_SEL — need_des
0x158 LCDCAM_CAM_CTRL0 — need_des
  [26:19] REG_CAM_CLK_DIV_DENOMINATOR — need_des
  [18:11] REG_CAM_CLK_DIV_NUMERATOR — need_des
  [10:3] REG_CAM_CLK_DIV_NUM — need_des
  [2] REG_CAM_CLK_EN — need_des
  [1:0] REG_CAM_CLK_SRC_SEL — need_des
0x15C IOMUX_CTRL0 reset 0x11 — need_des
  [12:5] REG_IOMUX_CLK_DIV_NUM — need_des
  [4] REG_IOMUX_CLK_EN — need_des
  [3] REG_IOMUX_CLK_SRC_SEL — need_des
  [2] REG_IOMUX_FORCE_NORST — need_des
  [1] REG_IOMUX_RST_EN — need_des
  [0] REG_IOMUX_APB_CLK_EN — need_des
0x160 HPWDT_CORE0_RST_CTRL0 reset 0x1011 — need_des
  [16:9] REG_WDT_HPCORE0_RST_LEN — need_des
  [8:1] REG_HPCORE0_STALL_WAIT_NUM — need_des
  [0] REG_HPCORE0_STALL_EN — need_des
0x164 HPWDT_CORE1_RST_CTRL0 reset 0x1011 — need_des
  [16:9] REG_WDT_HPCORE1_RST_LEN — need_des
  [8:1] REG_HPCORE1_STALL_WAIT_NUM — need_des
  [0] REG_HPCORE1_STALL_EN — need_des
0x168 CPU_SRC_FREQ0 ro — CPU Source Frequency
  [31:0] REG_CPU_SRC_FREQ — cpu source clock frequency, step by 0.25MHz
0x16C CPU_CLK_STATUS0 ro — CPU Clock Status
  [16:14] REG_CPU_DIV_DENOMINATOR_CUR — cpu current div denominator
  [13:11] REG_CPU_DIV_NUMERATOR_CUR — cpu current div numerator
  [10:3] REG_CPU_DIV_NUM_CUR — cpu current div number
  [2] REG_CPU_SRC_IS_CPLL — 0: CPU source isn't cpll_400m, 1: CPU Source is cll_400m
  [1] REG_CPU_DIV_EFFECT — 0: Divider bypass, 1: Divider takes effect
  [0] REG_ASIC_OR_FPGA — 0: ASIC mode, 1: FPGA mode
0x170 HPCORE_WDT_RESET_SOURCE0 reset 0x2 — need_des
  [1] REG_HPCORE1_WDT_RESET_SOURCE_SEL — 1'b0: use wdt0 to reset hpcore1, 1'b1: use wdt1 to reset hpcore1
  [0] REG_HPCORE0_WDT_RESET_SOURCE_SEL — 1'b0: use wdt0 to reset hpcore0, 1'b1: use wdt1 to reset hpcore0
0x174 ANA_PLL_CTRL0 access per field — need_des
  [10] REG_PLL_CAL_END ro — need_des
  [9] REG_MSPI_CAL_STOP rw — need_des
  [8] REG_MSPI_CAL_END ro — need_des
  [7] REG_BBPLL_CAL_STOP rw — need_des
  [6] REG_BBPLL_CAL_END ro — need_des
  [5] REG_SDIO_PLL_CAL_STOP rw — need_des
  [4] REG_SDIO_PLL_CAL_END ro — need_des
  [3] REG_CPU_PLL_CAL_STOP rw — need_des
  [2] REG_CPU_PLL_CAL_END ro — need_des
  [1] REG_PLLA_CAL_STOP rw — need_des
  [0] REG_PLLA_CAL_END ro — need_des
0x178 REF_500M_CTRL0 — need_des
  [0] REG_REF_500M_SEL
0x17C REF_240M_CTRL0 reset 0x101 — need_des
  [8] REG_REF_240M_CLK_EN — need_des
  [7:0] REG_REF_240M_CLK_DIV_NUM — need_des
0x180 REF_160M_CTRL0 reset 0x102 — need_des
  [8] REG_REF_160M_CLK_EN — need_des
  [7:0] REG_REF_160M_CLK_DIV_NUM — need_des
0x184 REF_120M_CTRL0 reset 0x103 — need_des
  [8] REG_REF_120M_CLK_EN — need_des
  [7:0] REG_REF_120M_CLK_DIV_NUM — need_des
0x188 REF_80M_CTRL0 reset 0x505 — need_des
  [10] REG_REF_80M_MUX_CLK_EN — need_des
  [9] REG_REF_80M_SEL — need_des
  [8] REG_REF_80M_CLK_EN — need_des
  [7:0] REG_REF_80M_CLK_DIV_NUM — need_des
0x18C REF_60M_CTRL0 reset 0x107 — need_des
  [8] REG_REF_60M_CLK_EN — need_des
  [7:0] REG_REF_60M_CLK_DIV_NUM — need_des
0x190 REF_20M_CTRL0 reset 0x117 — need_des
  [8] REG_REF_20M_CLK_EN — need_des
  [7:0] REG_REF_20M_CLK_DIV_NUM — need_des
0x194 REF_50M_CTRL0 reset 0x105 — need_des
  [8] REG_REF_50M_CLK_EN — need_des
  [7:0] REG_REF_50M_CLK_DIV_NUM — need_des
0x198 REF_25M_CTRL0 reset 0x10B — need_des
  [8] REG_REF_25M_CLK_EN — need_des
  [7:0] REG_REF_25M_CLK_DIV_NUM — need_des
0x19C TM_CLK_CTRL0 — need_des
  [8] REG_TM_250M_CLK_EN — need_des
  [7] REG_TM_20M_CLK_EN — need_des
  [6] REG_TM_48M_CLK_EN — need_des
  [5] REG_TM_60M_CLK_EN — need_des
  [4] REG_TM_80M_CLK_EN — need_des
  [3] REG_TM_120M_CLK_EN — need_des
  [2] REG_TM_160M_CLK_EN — need_des
  [1] REG_TM_240M_CLK_EN — need_des
  [0] REG_TM_480M_CLK_EN — need_des
{0x1A0+4i} DBG{i}_CLK_CTRL0 reset 0x3FF (i=0..2) — need_des
  [16] REG_DBG_CH{i}_EN — need_des
  [15:8] REG_DBG_CH{i}_DIV_NUM — need_des
  [7:0] REG_DBG_CH{i}_SEL — need_des
0x1AC LP_CLK_CTRL0 — need_des
  [2] REG_LPAON_PLL80M_CLK_FORCE_ON — need_des
  [1] REG_LPAON_XTAL_CLK_FORCE_ON — need_des
  [0] REG_LPAON_FOSC_CLK_FORCE_ON — need_des
0x1B0 AHB_ASRC_CTRL0 reset 0x1 — need_des
  [2] REG_AHB_ASRC_FORCE_NORST — need_des
  [1] REG_AHB_ASRC_RST_EN — need_des
  [0] REG_AHB_ASRC_SYS_CLK_EN — need_des
0x1B4 CORDIC_CTRL0 — need_des
  [8:7] REG_CORDIC_CLK_SRC_SEL — need_des
  [6] REG_CORDIC_FORCE_NORST — need_des
  [5] REG_CORDIC_CORE_RST_EN — need_des
  [4] REG_CORDIC_CLK_EN — need_des
  [3] REG_CORDIC_SYS_RST_EN — need_des
  [2] REG_CORDIC_SYS_CLK_EN — need_des
  [1] REG_CORDIC_APB_RST_EN — need_des
  [0] REG_CORDIC_APB_CLK_EN — need_des
0x1B8 ZERO_DET_CTRL0 — need_des
  [14:7] REG_ZERO_DET_CLK_DIV_NUM — need_des
  [6:5] REG_ZERO_DET_CLK_SRC_SEL — need_des
  [4] REG_ZERO_DET_FORCE_NORST — need_des
  [3] REG_ZERO_DET_CORE_RST_EN — need_des
  [2] REG_ZERO_DET_CLK_EN — need_des
  [1] REG_ZERO_DET_APB_RST_EN — need_des
  [0] REG_ZERO_DET_APB_CLK_EN — need_des
0x1BC CORDIC_CTRL1 — need_des
  [23:16] REG_CORDIC_CLK_DIV_DENONIMATOR — need_des
  [15:8] REG_CORDIC_CLK_DIV_NUMERATOR — need_des
  [7:0] REG_CORDIC_CLK_DIV_NUM — need_des
0x1C8 CLK_PWR_DECREASE — need_des
  [8] REG_CPU_WFI_DECREASE_EN — need_des
  [7:0] REG_APB_HW_DECREASE_DIV_NUM — need_des
0x1CC CNNT_IOMUX_CTRL0 reset 0x1 — need_des
  [0] REG_CNNT_IOMUX_APB_CLK_EN — cnnt_iomux clk en
0x1D0 HP_I2CMST_CTRL0 reset 0x1 — need_des
  [2] REG_HP_I2CMST_FORCE_NORST — need_des
  [1] REG_HP_I2CMST_RST_EN — need_des
  [0] REG_HP_I2CMST_APB_CLK_EN — need_des
0x1D4 AXI_PERF_MON_CTRL0 — need_des
  [2] REG_AXI_PERF_MON_FORCE_NORST — need_des
  [1] REG_AXI_PERF_MON_CLK_EN — axi_perf_mon clk en
  [0] REG_AXI_PERF_MON_RST_EN — axi_perf_mon rst en
0x1D8 CNNT_SYSREG_CTRL0 reset 0x1 — need_des
  [0] REG_CNNT_SYSREG_SYS_CLK_EN — cnnt_sysreg clk en
0x1DC HP_ALIVE_SYSREG_CTRL0 reset 0x1 — need_des
  [0] REG_HP_ALIVE_SYSREG_APB_CLK_EN — hp alive_sysreg clk en
0x1E0 MODEM_CONF reset 0x25 — MODEM_APB configuration register
  [5] MODEM_XTAL_CLK_EN — modem clk source xtal on
  [4] MODEM_PLL_CLK_EN — modem clk source pll on
  [3] MODEM_CLK_SOURCE_SEL
  [2] MODEM_CLK_EN — This field indicates if modem source clock is enable. 0: disable, 1: enable(default).
  [1] MODEM_RST_EN — Set this file as 1 to reset modem-subsystem.
  [0] MODEM_APB_CLK_EN — This field indicates if modem_apb clock is enable. 0: disable, 1: enable(default).
0x1E4 ADC_DAC_INV_PHASE_CONF — xxxx
  [2] CLK_PWDET_ADC_INV_PHASE_ENA — xxxx
  [1] CLK_TX_DAC_INV_PHASE_ENA — xxxx
  [0] CLK_RX_ADC_INV_PHASE_ENA — xxxx
0x1E8 PWDET_SAR_CLK_CONF reset 0x107 — xxxx
  [8] PWDET_SAR_CLK_EN — xxxx
  [7:0] PWDET_SAR_CLK_DIV_NUM — xxxx
0x1EC PAD_BIST_SDIO reset 0xC — need_des
  [10] RST_EN — need_des
  [9] IN_CLK_EN — need_des
  [8:6] IN_CLK_SEL — need_des
  [5:2] OUT_CLK_DIV_NUM — need_des
  [1] OUT_CLK_EN — need_des
  [0] OUT_CLK_SEL — need_des
0x1F0 PAD_BIST_GMAC0 reset 0x4 — need_des
  fields as PAD_BIST_SDIO
0x1F4 PAD_BIST_GMAC1 reset 0x4 — need_des
  fields as PAD_BIST_SDIO
0x1F8 CLK_EN0 reset 0x1 — need_des
  [0] REG_CLK_EN
0x1FC DATE reset 0x2509110 — need_des
  [27:0] REG_DATE — Version control register
